# RL6955_IP_SVD register map
Vendor: Realtek
Registers are 32-bit, read-write, reset 0x0 unless marked. A register's access mark holds for its fields unless they carry their own. Offsets are from the block's base; [hi:lo] are bit positions; {n}, {i} and the like mark numbered series; <NAME> marks a mode.

## PPE_REG
Base 0x41900000
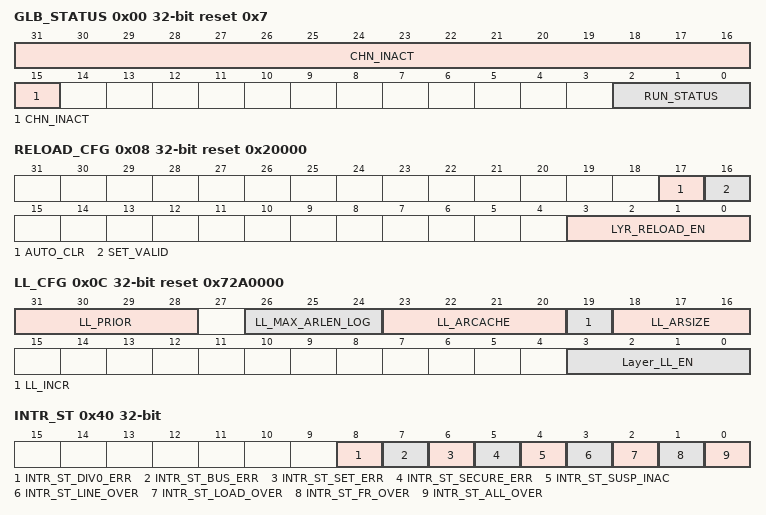
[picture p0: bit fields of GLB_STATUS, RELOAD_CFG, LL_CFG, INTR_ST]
0x00 GLB_STATUS access per field reset 0x7 — Global status Register
  [31:15] CHN_INACT ro — Indicates whether the internal DMA channels are inactive (protocol over). Bit 15: 0x0: There are currently outstanding transactions for AWID=0 0x1: There are currently no outstanding transactions for AWID=0 Bit i (16 <= i <= 31): 0x0: There are currently outstanding transactions for ARID=i-16 0x1: There are currently no outstanding transactions for ARID=i-16
  [2:0] RUN_STATUS rw — Run status 0x0: Disabled 0x1: Runing 0x2: Inactive (w/o outstanding) 0x3: Suspend (w/ outstanding) Others: reserved
0x04 LAY_EN — Layer enable register
  [3:1] INPUT_LAY_EN — Input layers enable field. Bit i (1 <= i <=3 ) 0x0: Input layer i is disabled. 0x1: Input layer i is enabled.
0x08 RELOAD_CFG reset 0x20000 — Reload configuration Register
  [17] AUTO_CLR — Auto clear "SET_VALID" after loading layer settings
  [16] SET_VALID — Setting is valid Will be auto set to 1 when writing 1 to GLB_EN
  [3:0] LYR_RELOAD_EN — Layers setting reload enable Bit0~15: Layer0~15
0x0C LL_CFG access per field reset 0x72A0000 — Linked List configuration Register
  [31:28] LL_PRIOR ro — Priority (ARQos) (Reserved)
  [26:24] LL_MAX_ARLEN_LOG ro — Limit of ARLen (Reserved)
  [23:20] LL_ARCACHE ro — ARCache (Reserved). Refer to AXI4 protocol.
  [19] LL_INCR ro — INCR or FIXED burst for reading linked list item (Reserved)
  [18:16] LL_ARSIZE ro — ARSize for reading linked list item (Reserved)
  [3:0] Layer_LL_EN rw — Update layers registers by linked list enable Bit0~15: Layer0~15
0x10 LLP — Linked List Pointer Register
  [31:0] LLP — Linked List Pointer Note: Must align to 4 Bytes. Bits[1:0] is read only and return 0 on a read.
0x18 MISC ro — Secure enable register
  [0] SECURE — Secure enable This field can only be modified by secure APB transaction. 0x0: PPE in non-secure mode 0x1: PPE in secure mode
0x1C LINE_INDEX reset 0x7FF
  [10:0] LINE_INDEX — Line index for line over interrupt LINE_OVER interrupt is raised when the transaction of last pixel of this index marked line has been completed.
0x20 RELEASE_DATE ro
0x24 RTL_VERSION ro
0x40 INTR_ST ro — Interrupt status (raw & mask) register
  [8] INTR_ST_DIV0_ERR, [7] INTR_ST_BUS_ERR, [6] INTR_ST_SET_ERR, [5] INTR_ST_SECURE_ERR, [4] INTR_ST_SUSP_INAC, [3] INTR_ST_LINE_OVER, [2] INTR_ST_LOAD_OVER, [1] INTR_ST_FR_OVER, [0] INTR_ST_ALL_OVER
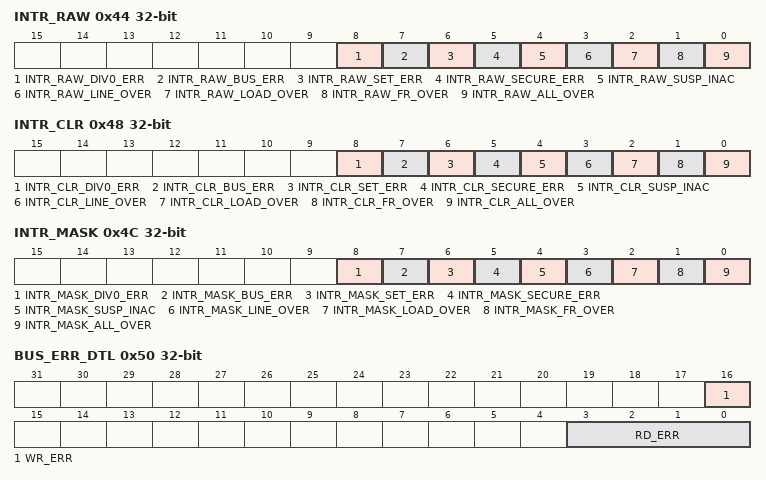
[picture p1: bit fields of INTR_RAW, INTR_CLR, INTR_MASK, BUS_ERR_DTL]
0x44 INTR_RAW ro — Interrupt raw status register
  [8] INTR_RAW_DIV0_ERR
  [7] INTR_RAW_BUS_ERR
  [6] INTR_RAW_SET_ERR — Setting error (Reserved)
  [5] INTR_RAW_SECURE_ERR — Secure error Raised after non-secure APB request access secure PPE.
  [4] INTR_RAW_SUSP_INAC — Master port inactive after being suspended Raised after the master port is inactive and PPE is suspended.
  [3] INTR_RAW_LINE_OVER — Line index over Raised after the transaction of last pixel of LINE_INDEX marked line has been completed.
  [2] INTR_RAW_LOAD_OVER — Register load over Raised after layers registers load to internal DMA.
  [1] INTR_RAW_FR_OVER — Frame over Raised after every frame completion.
  [0] INTR_RAW_ALL_OVER — All frames over Raised after all frames completion.
0x48 INTR_CLR wo — Interrupt clear register
  [8] INTR_CLR_DIV0_ERR — Wirte 1 to clear the corresponding interrupt
  [7] INTR_CLR_BUS_ERR — Wirte 1 to clear the corresponding interrupt
  [6] INTR_CLR_SET_ERR — Wirte 1 to clear the corresponding interrupt
  [5] INTR_CLR_SECURE_ERR — Wirte 1 to clear the corresponding interrupt
  [4] INTR_CLR_SUSP_INAC — Wirte 1 to clear the corresponding interrupt
  [3] INTR_CLR_LINE_OVER — Wirte 1 to clear the corresponding interrupt
  [2] INTR_CLR_LOAD_OVER — Wirte 1 to clear the corresponding interrupt
  [1] INTR_CLR_FR_OVER — Wirte 1 to clear the corresponding interrupt
  [0] INTR_CLR_ALL_OVER — Wirte 1 to clear the corresponding interrupt
0x4C INTR_MASK — Interrupt mask register
  [8] INTR_MASK_DIV0_ERR, [7] INTR_MASK_BUS_ERR, [6] INTR_MASK_SET_ERR, [5] INTR_MASK_SECURE_ERR, [4] INTR_MASK_SUSP_INAC, [3] INTR_MASK_LINE_OVER, [2] INTR_MASK_LOAD_OVER, [1] INTR_MASK_FR_OVER, [0] INTR_MASK_ALL_OVER
0x50 BUS_ERR_DTL ro — BUS error detail register
  [16] WR_ERR — The mark for write error response Assert this bit when receiving error response from axi B cahnnel
  [3:0] RD_ERR — The mark for read error response Assert bit N when receiving error response from axi_rid=N
0x58 XOR_CTRL reset 0x1 — XOR control register
  [0] XOR — 0x1: Enable XOR function 0x0: Disable XOR function
0x60 RESULT_LAYER_ADDR_L — Address of the first pixel register
  [31:0] RESULT_LAYER_ADDR_L — Address of the first pixel (Physical address)
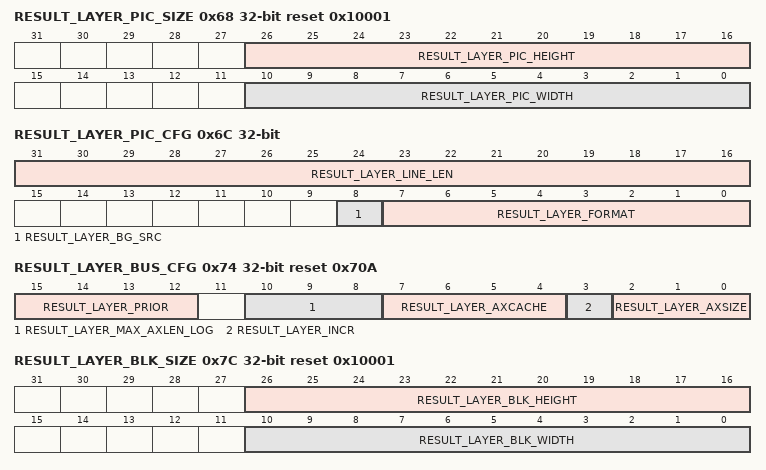
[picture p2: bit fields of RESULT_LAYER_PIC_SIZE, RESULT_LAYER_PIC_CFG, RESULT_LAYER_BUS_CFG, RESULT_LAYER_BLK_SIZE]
0x68 RESULT_LAYER_PIC_SIZE reset 0x10001 — Canvas size register
  [26:16] RESULT_LAYER_PIC_HEIGHT — Canvas height (in pixels) Must be greater than 0.
  [10:0] RESULT_LAYER_PIC_WIDTH — Canvas width (in pixels) Must be greater than 0.
0x6C RESULT_LAYER_PIC_CFG — Picture configuration register
  [31:16] RESULT_LAYER_LINE_LEN — Indicates the bytes in memory between two vertically adjacent pixels.
  [8] RESULT_LAYER_BG_SRC — Background source 0x0: Use CONST_BG as background 0x1: Use lyr1 as background
  [7:0] RESULT_LAYER_FORMAT — Pixel format
0x70 RESULT_LAYER_CONST_BG — Constant background color register
  [31:0] RESULT_LAYER_ABGR — Background ABGR (in ABGR8888 format)
0x74 RESULT_LAYER_BUS_CFG access per field reset 0x70A — Master port BUS configuration register
  [15:12] RESULT_LAYER_PRIOR rw — Priority (AWQos)
  [10:8] RESULT_LAYER_MAX_AXLEN_LOG rw — Limit of AWLen
  [7:4] RESULT_LAYER_AXCACHE rw — AWCache Refer to AXI4 protocol.
  [3] RESULT_LAYER_INCR ro — AWBurst 0x1: AWBurst = INCR 0x0: AWBurst = FIXED
  [2:0] RESULT_LAYER_AXSIZE rw — AWSize Refer to AXI4 protocol. (AXI cmd size must be less than or equal to BUS width)
0x7C RESULT_LAYER_BLK_SIZE reset 0x10001 — Canvas size register
  [26:16] RESULT_LAYER_BLK_HEIGHT — Block height (in pixels) Must be greater than 0 and less than or equal to canvas width.
  [10:0] RESULT_LAYER_BLK_WIDTH — Block width (in pixels) Must be greater than 0 and less than or equal to canvas width.
{0x0+0x80*i} INPUT_LAYER{i}_ADDR_L (i=1..3) — Address of the first pixel register
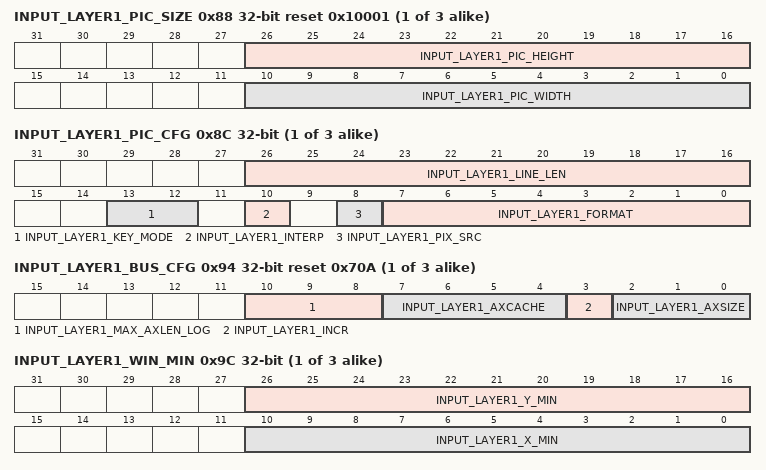
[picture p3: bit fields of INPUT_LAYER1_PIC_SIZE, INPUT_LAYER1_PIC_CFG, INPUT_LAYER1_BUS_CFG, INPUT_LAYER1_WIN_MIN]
{0x8+0x80*i} INPUT_LAYER{i}_PIC_SIZE reset 0x10001 (i=1..3) — Canvas size register
  [26:16] INPUT_LAYER{i}_PIC_HEIGHT — Picture height (in pixels) Must be greater than 0.
  [10:0] INPUT_LAYER{i}_PIC_WIDTH — Picture width (in pixels) Must be greater than 0.
{0xC+0x80*i} INPUT_LAYER{i}_PIC_CFG (i=1..3) — Picture configuration register
  [26:16] INPUT_LAYER{i}_LINE_LEN — Indicates the bytes in memory between two vertically adjacent pixels.
  [13:12] INPUT_LAYER{i}_KEY_MODE — Color keying match mode 0x0, 0x1: Disable 0x2: Inside ((Rmin<=R<=Rmax) & (Gmin<=G<=Gmax) & (Bmin<=B<=Bmax)) 0x3: Outside ((R<Rmin) | (R>Rmax) | (G<Gmin) | (G>Gmax) | (B<Bmin) | (B>Bmax))
  [10] INPUT_LAYER{i}_INTERP — Interpolation 0x0: Nearest-neighbor 0x1: Bilinear
  [8] INPUT_LAYER{i}_PIX_SRC — Pixel source: 0x0: CONST_PIX 0x1: DMA (read from memory)
  [7:0] INPUT_LAYER{i}_FORMAT — Format of pixels from memory
{0x10+0x80*i} INPUT_LAYER{i}_CONST_PIX reset 0xFFFFFFFF (i=1..3) — Constant pixel register
  [31:0] INPUT_LAYER{i}_ABGR — In ABGR8888 format
{0x14+0x80*i} INPUT_LAYER{i}_BUS_CFG access per field reset 0x70A (i=1..3) — Master port BUS configuration register
  [10:8] INPUT_LAYER{i}_MAX_AXLEN_LOG rw — Limit of ARLen
  [7:4] INPUT_LAYER{i}_AXCACHE rw — ARCache Refer to AXI4 protocol. Note: Set to 0x6 to enable read buffer for input layer
  [3] INPUT_LAYER{i}_INCR ro — ARBurst 0x1: ARBurst = INCR 0x0: ARBurst = FIXED
  [2:0] INPUT_LAYER{i}_AXSIZE rw — ARSize Refer to AXI4 protocol. · AXI cmd size must be less than or equal to BUS width. · Must be 0x2 when AXCACHE=6.
{0x1C+0x80*i} INPUT_LAYER{i}_WIN_MIN (i=1..3) — Minimum coordinate of the input window register
  [26:16] INPUT_LAYER{i}_Y_MIN — Y coordinate
  [10:0] INPUT_LAYER{i}_X_MIN — X coordinate
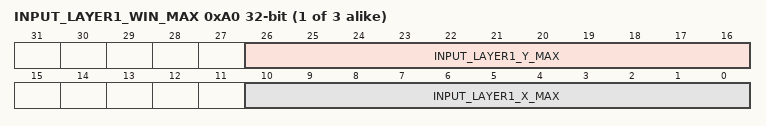
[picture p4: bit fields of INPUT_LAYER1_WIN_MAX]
{0x20+0x80*i} INPUT_LAYER{i}_WIN_MAX (i=1..3) — Maximum coordinate of the input window register
  [26:16] INPUT_LAYER{i}_Y_MAX — Y coordinate
  [10:0] INPUT_LAYER{i}_X_MAX — X coordinate
{0x24+0x80*i} INPUT_LAYER{i}_KEY_MIN (i=1..3) — Minimum of the color key match condition register
  [23:0] INPUT_LAYER{i}_BGR_MIN — Minimum BGR of the color key match condition In BGR888 format.
{0x28+0x80*i} INPUT_LAYER{i}_KEY_MAX (i=1..3) — Maximum of the color key match condition register
  [23:0] INPUT_LAYER{i}_BGR_MAX — Maximum BGR of the color key match condition In BGR888 format.
{0x2C+0x80*i} INPUT_LAYER{i}_MATRIX_E11 reset 0x10 (i=1..3) — Matrix E11 register
  [15:0] INPUT_LAYER{i}_MATRIX_E11 — Element E11 ~ E33 of coordinates transformation matrix
{0x30+0x80*i} INPUT_LAYER{i}_MATRIX_E12 (i=1..3) — Matrix E12 register
  [15:0] INPUT_LAYER{i}_MATRIX_E12 — Element E11 ~ E33 of coordinates transformation matrix · Elements E12, E21, E31~E33 are RO if SUPPORT_ROTATION_i = 0.
{0x34+0x80*i} INPUT_LAYER{i}_MATRIX_E13 (i=1..3) — Matrix E13 register
  [15:0] INPUT_LAYER{i}_MATRIX_E13 — Element E11 ~ E33 of coordinates transformation matrix
{0x38+0x80*i} INPUT_LAYER{i}_MATRIX_E21 (i=1..3) — Matrix E21 register
  [15:0] INPUT_LAYER{i}_MATRIX_E21 — Element E11 ~ E33 of coordinates transformation matrix · Elements E12, E21, E31~E33 are RO if SUPPORT_ROTATION_i = 0.
{0x3C+0x80*i} INPUT_LAYER{i}_MATRIX_E22 reset 0x10 (i=1..3) — Matrix E22 register
  [15:0] INPUT_LAYER{i}_MATRIX_E22 — Element E11 ~ E33 of coordinates transformation matrix
{0x40+0x80*i} INPUT_LAYER{i}_MATRIX_E23 (i=1..3) — Matrix E23 register
  [15:0] INPUT_LAYER{i}_MATRIX_E23 — Element E11 ~ E33 of coordinates transformation matrix
{0x44+0x80*i} INPUT_LAYER{i}_MATRIX_E31 ro (i=1..3) — Matrix E31 register
  [31:0] INPUT_LAYER{i}_MATRIX_E31 — Element E11 ~ E33 of coordinates transformation matrix · Elements E12, E21, E31~E33 are RO if SUPPORT_ROTATION_i = 0. · Elements E31~E33 are RO if SUPPORT_PERSPECTIVE_i = 0.
{0x48+0x80*i} INPUT_LAYER{i}_MATRIX_E32 ro (i=1..3) — Matrix E32 register
  [31:0] INPUT_LAYER{i}_MATRIX_E32 — Element E11 ~ E33 of coordinates transformation matrix · Elements E12, E21, E31~E33 are RO if SUPPORT_ROTATION_i = 0. · Elements E31~E33 are RO if SUPPORT_PERSPECTIVE_i = 0.
{0x4C+0x80*i} INPUT_LAYER{i}_MATRIX_E33 ro reset 0x10 (i=1..3) — Matrix E33 register
  [31:0] INPUT_LAYER{i}_MATRIX_E33 — Element E11 ~ E33 of coordinates transformation matrix · Elements E12, E21, E31~E33 are RO if SUPPORT_ROTATION_i = 0. · Elements E31~E33 are RO if SUPPORT_PERSPECTIVE_i = 0.
